# STM32L0x0 register map
File version: 1.3
CPU: CM0+ r0p0, little endian, MPU, no FPU, 2 interrupt priority bits
Registers are 32-bit, read-write, reset 0x0 unless marked. A register's access mark holds for its fields unless they carry their own. Offsets are from the block's base; [hi:lo] are bit positions; {n}, {i} and the like mark numbered series; 'fields as' and 'values as' point back to an identical list.

## SYSCFG — System configuration controller register
Base 0x40010000
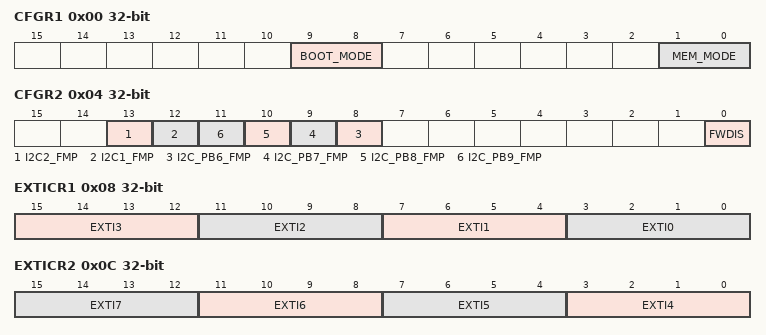
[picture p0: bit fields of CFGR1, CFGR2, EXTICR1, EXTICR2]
0x00 CFGR1 access per field — SYSCFG configuration register 1
  [9:8] BOOT_MODE ro — Boot mode selected by the boot pins status bits
    0=Main Flash memory boot mode; 1=System Flash memory boot mode; 3=SRAM (Embedded SRAM boot mode)
  [1:0] MEM_MODE rw — Memory mapping selection bits
    0=Main Flash memory mapped at 0x0000_0000; 1=System Flash memory mapped at 0x0000_0000; 3=SRAM (Embedded SRAM mapped at 0x0000_0000)
0x04 CFGR2 — SYSCFG configuration register 2
  [13] I2C2_FMP — I2C2 Fm+ drive capability enable bit
  [12] I2C1_FMP — I2C1 Fm+ drive capability enable bit
  [n+2] I2C_PB{n}_FMP (n=6..9) — Fm+ drive capability on PB{n} enable bit
  [0] FWDIS — Firewall disable bit
0x08 EXTICR1 — external interrupt configuration register 1
  [15:12] EXTI3 — EXTI x configuration (x = 0 to 3)
    0=PA (Select PAx as the source input for the EXTIx external interrupt); 1=PB (Select PBx as the source input for the EXTIx external interrupt); 2=PC (Select PCx as the source input for the EXTIx external interrupt); 3=PD (Select PDx as the source input for the EXTIx external interrupt); 4=PE (Select PEx as the source input for the EXTIx external interrupt)
  [11:8] EXTI2 — EXTI x configuration (x = 0 to 3)
    values as EXTI3
  [7:4] EXTI1 — EXTI x configuration (x = 0 to 3)
    0=PA (Select PAx as the source input for the EXTIx external interrupt); 1=PB (Select PBx as the source input for the EXTIx external interrupt); 2=PC (Select PCx as the source input for the EXTIx external interrupt); 3=PD (Select PDx as the source input for the EXTIx external interrupt); 4=PE (Select PEx as the source input for the EXTIx external interrupt); 5=PH (Select PHx as the source input for the EXTIx external interrupt)
  [3:0] EXTI0 — EXTI x configuration (x = 0 to 3)
    values as EXTI1
0x0C EXTICR2 — external interrupt configuration register 2
  [all] fields
    values as EXTICR1.EXTI3
  [4n-13:4n-16] EXTI{n} (n=4..7) — EXTI x configuration (x = 4 to 7)
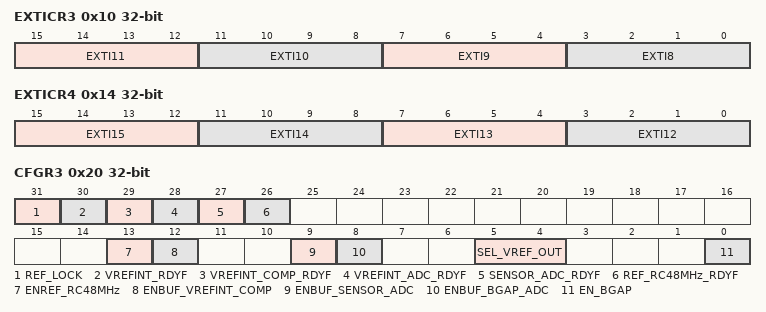
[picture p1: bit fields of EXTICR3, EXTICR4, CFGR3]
0x10 EXTICR3 — external interrupt configuration register 3
  [15:12] EXTI11 — EXTI x configuration (x = 8 to 11)
    values as EXTICR1.EXTI1
  [11:8] EXTI10
    values as EXTICR1.EXTI1
  [7:4] EXTI9 — EXTI x configuration (x = 8 to 11)
    values as EXTICR1.EXTI1
  [3:0] EXTI8 — EXTI x configuration (x = 8 to 11)
    values as EXTICR1.EXTI3
0x14 EXTICR4 — external interrupt configuration register 4
  [all] fields
    values as EXTICR1.EXTI3
  [15:12] EXTI15 — EXTI x configuration (x = 12 to 15)
  [11:8] EXTI14
  [7:4] EXTI13
  [3:0] EXTI12
0x20 CFGR3 access per field — SYSCFG configuration register 3
  [31] REF_LOCK wo — REF_CTRL lock bit
    0=ReadWrite (SYSCFG_CFGR3[31:0] bits are read/write); 1=ReadOnly (SYSCFG_CFGR3[31:0] bits are read-only)
  [30] VREFINT_RDYF ro — VREFINT ready flag
    0=NotReady (VREFINT OFF); 1=Ready (VREFINT ready)
  [29] VREFINT_COMP_RDYF ro — VREFINT for comparator ready flag
  [28] VREFINT_ADC_RDYF ro — VREFINT for ADC ready flag
  [27] SENSOR_ADC_RDYF ro — Sensor for ADC ready flag
  [26] REF_RC48MHz_RDYF ro — VREFINT for 48 MHz RC oscillator ready flag
  [13] ENREF_RC48MHz rw — VREFINT reference for 48 MHz RC oscillator enable bit
  [12] ENBUF_VREFINT_COMP rw — VREFINT reference for comparator 2 enable bit
  [9] ENBUF_SENSOR_ADC rw — Sensor reference for ADC enable bit
    0=Disabled (Disables the buffer used to generate VREFINT reference for the temperature sensor); 1=Enabled (Enables the buffer used to generate VREFINT reference for the temperature sensor)
  [8] ENBUF_BGAP_ADC rw — VREFINT reference for ADC enable bit
  [5:4] SEL_VREF_OUT rw — BGAP_ADC connection bit
    0=NoConnection (no pad connected); 1=PB0 (PB0 connected); 2=PB1 (PB1 connected); 3=Both (PB0 and PB1 connected)
  [0] EN_BGAP rw — Vref Enable bit
